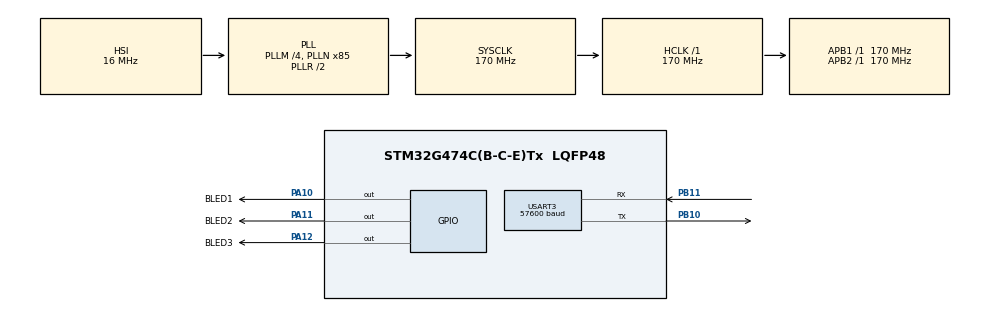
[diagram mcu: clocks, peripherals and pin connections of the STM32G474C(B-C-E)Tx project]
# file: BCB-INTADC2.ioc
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Mcu.Family=STM32G4
Mcu.Name=STM32G474C(B-C-E)Tx
Mcu.Package=LQFP48
NVIC.PriorityGroup=NVIC_PRIORITYGROUP_4
NVIC.USART3_IRQn=true\:0\:0\:false\:false\:true\:true\:true\:true
PA10.GPIO_Label=BLED1
PA10.Signal=GPIO_Output
PA11.GPIO_Label=BLED2
PA11.Signal=GPIO_Output
PA12.GPIO_Label=BLED3
PA12.Signal=GPIO_Output
PA13.Mode=JTAG_4_pins
PA13.Signal=SYS_JTMS-SWDIO
PA14.Mode=JTAG_4_pins
PA14.Signal=SYS_JTCK-SWCLK
PA15.Mode=JTAG_4_pins
PA15.Signal=SYS_JTDI
PA8.GPIO_Label=PFC
PA8.Signal=S_TIM1_CH1
PA9.GPIO_Label=V24_SENSE
PA9.Signal=ADC5_IN2
PB10.Mode=Asynchronous
PB10.Signal=USART3_TX
PB11.Mode=Asynchronous
PB11.Signal=USART3_RX
PB3.Mode=JTAG_4_pins
PB3.Signal=SYS_JTDO-SWO
ProjectManager.HeapSize=0x200
ProjectManager.StackSize=0x400
ProjectManager.TargetToolchain=STM32CubeIDE
RCC.ADC12Freq_Value=170000000
RCC.ADC345Freq_Value=170000000
RCC.AHBFreq_Value=170000000
RCC.APB1Freq_Value=170000000
RCC.APB1TimFreq_Value=170000000
RCC.APB2Freq_Value=170000000
RCC.APB2TimFreq_Value=170000000
RCC.CortexFreq_Value=170000000
RCC.EXTERNAL_CLOCK_VALUE=12288000
RCC.HCLKFreq_Value=170000000
RCC.HSE_VALUE=8000000
RCC.HSI48_VALUE=48000000
RCC.HSI_VALUE=16000000
RCC.LSE_VALUE=32768
RCC.PLLM=RCC_PLLM_DIV4
RCC.PLLN=85
RCC.SYSCLKFreq_VALUE=170000000
RCC.SYSCLKSource=RCC_SYSCLKSOURCE_PLLCLK
RCC.USBFreq_Value=170000000
RCC.VCOOutputFreq_Value=340000000
SH.S_TIM1_CH1.0=TIM1_CH1
USART3.BaudRate=57600
USART3.VirtualMode-Asynchronous=VM_ASYNC
VP_SYS_VS_DBSignals.Mode=DisableDeadBatterySignals
VP_SYS_V_VREFBUF.Mode=ExternalMode
board=custom

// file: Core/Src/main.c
/* USER CODE BEGIN Header */
/**
  ******************************************************************************
  * @file           : main.c
  * @brief          : Main program body
  ******************************************************************************
  * @attention
  *
  * Copyright (c) 2025 STMicroelectronics.
  * All rights reserved.
  *
  * This software is licensed under terms that can be found in the LICENSE file
  * in the root directory of this software component.
  * If no LICENSE file comes with this software, it is provided AS-IS.
  *
  ******************************************************************************
  */
/* USER CODE END Header */
#include "main.h"

UART_HandleTypeDef huart3;

void SystemClock_Config(void);
static void MX_GPIO_Init(void);
static void MX_USART3_UART_Init(void);

int main(void)
{

  /* MCU Configuration--------------------------------------------------------*/

  /* Reset of all peripherals, Initializes the Flash interface and the Systick. */
  HAL_Init();

  /* Configure the system clock */
  SystemClock_Config();

  /* Initialize all configured peripherals */
  MX_GPIO_Init();
  MX_USART3_UART_Init();

  /* Infinite loop */
  while (1)
  {

    /* USER CODE BEGIN 3 */
	  HAL_GPIO_TogglePin(BLED1_GPIO_Port, BLED1_Pin);
	  HAL_Delay(500);
  }
  /* USER CODE END 3 */
}

void SystemClock_Config(void)
{
  RCC_OscInitTypeDef RCC_OscInitStruct = {0};
  RCC_ClkInitTypeDef RCC_ClkInitStruct = {0};

  /** Configure the main internal regulator output voltage
  */
  HAL_PWREx_ControlVoltageScaling(PWR_REGULATOR_VOLTAGE_SCALE1_BOOST);

  /** Initializes the RCC Oscillators according to the specified parameters
  * in the RCC_OscInitTypeDef structure.
  */
  RCC_OscInitStruct.OscillatorType = RCC_OSCILLATORTYPE_HSI;
  RCC_OscInitStruct.HSIState = RCC_HSI_ON;
  RCC_OscInitStruct.HSICalibrationValue = RCC_HSICALIBRATION_DEFAULT;
  RCC_OscInitStruct.PLL.PLLState = RCC_PLL_ON;
  RCC_OscInitStruct.PLL.PLLSource = RCC_PLLSOURCE_HSI;
  RCC_OscInitStruct.PLL.PLLM = RCC_PLLM_DIV4;
  RCC_OscInitStruct.PLL.PLLN = 85;
  RCC_OscInitStruct.PLL.PLLP = RCC_PLLP_DIV2;
  RCC_OscInitStruct.PLL.PLLQ = RCC_PLLQ_DIV2;
  RCC_OscInitStruct.PLL.PLLR = RCC_PLLR_DIV2;
  if (HAL_RCC_OscConfig(&RCC_OscInitStruct) != HAL_OK)
  {
    Error_Handler();
  }

  /** Initializes the CPU, AHB and APB buses clocks
  */
  RCC_ClkInitStruct.ClockType = RCC_CLOCKTYPE_HCLK|RCC_CLOCKTYPE_SYSCLK
                              |RCC_CLOCKTYPE_PCLK1|RCC_CLOCKTYPE_PCLK2;
  RCC_ClkInitStruct.SYSCLKSource = RCC_SYSCLKSOURCE_PLLCLK;
  RCC_ClkInitStruct.AHBCLKDivider = RCC_SYSCLK_DIV1;
  RCC_ClkInitStruct.APB1CLKDivider = RCC_HCLK_DIV1;
  RCC_ClkInitStruct.APB2CLKDivider = RCC_HCLK_DIV1;

  if (HAL_RCC_ClockConfig(&RCC_ClkInitStruct, FLASH_LATENCY_4) != HAL_OK)
  {
    Error_Handler();
  }
}

static void MX_USART3_UART_Init(void)
{

  huart3.Instance = USART3;
  huart3.Init.BaudRate = 57600;
  huart3.Init.WordLength = UART_WORDLENGTH_8B;
  huart3.Init.StopBits = UART_STOPBITS_1;
  huart3.Init.Parity = UART_PARITY_NONE;
  huart3.Init.Mode = UART_MODE_TX_RX;
  huart3.Init.HwFlowCtl = UART_HWCONTROL_NONE;
  huart3.Init.OverSampling = UART_OVERSAMPLING_16;
  huart3.Init.OneBitSampling = UART_ONE_BIT_SAMPLE_DISABLE;
  huart3.Init.ClockPrescaler = UART_PRESCALER_DIV1;
  huart3.AdvancedInit.AdvFeatureInit = UART_ADVFEATURE_NO_INIT;
  if (HAL_UART_Init(&huart3) != HAL_OK)
  {
    Error_Handler();
  }
  if (HAL_UARTEx_SetTxFifoThreshold(&huart3, UART_TXFIFO_THRESHOLD_1_8) != HAL_OK)
  {
    Error_Handler();
  }
  if (HAL_UARTEx_SetRxFifoThreshold(&huart3, UART_RXFIFO_THRESHOLD_1_8) != HAL_OK)
  {
    Error_Handler();
  }
  if (HAL_UARTEx_DisableFifoMode(&huart3) != HAL_OK)
  {
    Error_Handler();
  }

}

static void MX_GPIO_Init(void)
{
  GPIO_InitTypeDef GPIO_InitStruct = {0};

  /* GPIO Ports Clock Enable */
  __HAL_RCC_GPIOB_CLK_ENABLE();
  __HAL_RCC_GPIOA_CLK_ENABLE();

  /*Configure GPIO pin Output Level */
  HAL_GPIO_WritePin(GPIOA, BLED1_Pin|BLED2_Pin|BLED3_Pin, GPIO_PIN_RESET);

  /*Configure GPIO pin : PFC_Pin */
  GPIO_InitStruct.Pin = PFC_Pin;
  GPIO_InitStruct.Mode = GPIO_MODE_AF_PP;
  GPIO_InitStruct.Pull = GPIO_NOPULL;
  GPIO_InitStruct.Speed = GPIO_SPEED_FREQ_LOW;
  GPIO_InitStruct.Alternate = GPIO_AF6_TIM1;
  HAL_GPIO_Init(PFC_GPIO_Port, &GPIO_InitStruct);

  /*Configure GPIO pin : V24_SENSE_Pin */
  GPIO_InitStruct.Pin = V24_SENSE_Pin;
  GPIO_InitStruct.Mode = GPIO_MODE_ANALOG;
  GPIO_InitStruct.Pull = GPIO_NOPULL;
  HAL_GPIO_Init(V24_SENSE_GPIO_Port, &GPIO_InitStruct);

  /*Configure GPIO pins : BLED1_Pin BLED2_Pin BLED3_Pin */
  GPIO_InitStruct.Pin = BLED1_Pin|BLED2_Pin|BLED3_Pin;
  GPIO_InitStruct.Mode = GPIO_MODE_OUTPUT_PP;
  GPIO_InitStruct.Pull = GPIO_NOPULL;
  GPIO_InitStruct.Speed = GPIO_SPEED_FREQ_LOW;
  HAL_GPIO_Init(GPIOA, &GPIO_InitStruct);

}

void Error_Handler(void)
{
  __disable_irq();
  while (1)
  {
  }
}
